# CY8C5888LTI_LP097 register map
File version: 0.1
CY8C58LP
Registers are 8-bit, read-write, no defined reset value unless marked. A register's access mark holds for its fields unless they carry their own. Offsets are from the block's base; lines under a group give offsets from that group; [hi:lo] are bit positions; {n}, {i} and the like mark numbered series; 'fields as' and 'values as' point back to an identical list; <NAME> marks a mode.

## Memory map
0x00000000 checkWatchDogTimer
0x00000000 SleepTimer
0x00000000 UART
0x00000000 PWM_Recon
0x00000000 Out_Comp
0x00000000 Bit_Timer

## checkWatchDogTimer
Base 0x00000000
0x40006504 checkWatchDogTimer_COUNTER 32-bit — UDB.A0 - Current Down Counter Value
0x40006524 checkWatchDogTimer_PERIOD 32-bit — UDB.D0 - Assigned Period
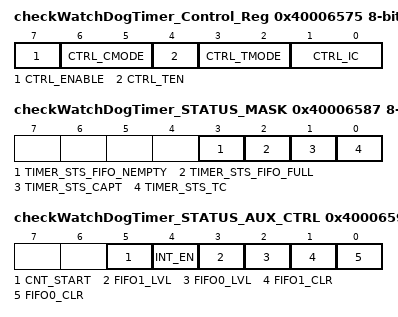
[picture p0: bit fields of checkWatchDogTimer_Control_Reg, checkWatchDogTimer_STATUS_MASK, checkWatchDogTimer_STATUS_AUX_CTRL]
0x40006575 checkWatchDogTimer_Control_Reg — UDB Control Register - Assigned Control Register Value
  [7] CTRL_ENABLE — Enable the Timer
  [6:5] CTRL_CMODE — Capture Mode
  [4] CTRL_TEN — Trigger Enable Bit
  [3:2] CTRL_TMODE — Trigger Mode
  [1:0] CTRL_IC — Interrupt Count
0x40006587 checkWatchDogTimer_STATUS_MASK — UDB Status bits Interrupt Mask Enable Register
  [3] TIMER_STS_FIFO_NEMPTY ro — FIFO Empty status
  [2] TIMER_STS_FIFO_FULL ro — FIFO Full Status
  [1] TIMER_STS_CAPT ro — Enables the Interrupt on Capture
  [0] TIMER_STS_TC ro — Enables the Interrupt on TC
0x40006597 checkWatchDogTimer_STATUS_AUX_CTRL — UDB Auxilliary Control Register
  [5] CNT_START — FIFO0 clear
    0=E_CNT_START0 (Disable counter); 1=E_CNT_START1 (Enable counter)
  [4] INT_EN
    0=E_INT_EN0 (Interrupt disabled); 1=E_INT_EN1 (Interrupt enabled)
  [3] FIFO1_LVL — FIFO level
    0=E_FIFO_LVL_0 (FIFO LVL: input mode: FIFO not full; output mode: FIFO not empty); 1=E_FIFO_LVL_1 (FIFO LVL: input mode: FIFO at least 1/2 empty; output mode: FIFO at least 1/2 full)
  [2] FIFO0_LVL — FIFO level
    values as FIFO1_LVL
  [1] FIFO1_CLR — FIFO1 clear
    0=E_FIFO_CLR_0 (Normal FIFO operation); 1=E_FIFO_CLR_1 (Clear FIFO state)
  [0] FIFO0_CLR — FIFO0 clear
    values as FIFO1_CLR

## SleepTimer
Base 0x00000000
0x40004381 SleepTimer_CTW_INTERVAL_REG — Timewheel Configuration Register 1
  [3:0] ctw_interval — Sets the central timewheel interval.
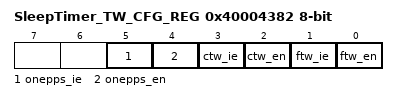
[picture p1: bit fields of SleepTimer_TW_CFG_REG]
0x40004382 SleepTimer_TW_CFG_REG — Timewheel Configuration Register 2
  [5] onepps_ie — When set and one pulse-per-second is enabled, an interrupt is issued when the pulse occurs.
    1=Enabled (One PPS interrupt is enabled); 0=Disabled (One PPS interrupt is disabled)
  [4] onepps_en — When set, the system returns to the active global power mode once every second.
    1=Enabled (One PPS is enabled); 0=Disabled (One PPS is disabled)
  [3] ctw_ie — When set and the central timewheel is enabled, an interrupt is issued when the central timewheel reaches the selected interval.
    1=Enabled (CTW interrupt is enabled); 0=Disabled (CTW interrupt is disabled)
  [2] ctw_en — When set, the system returns to the active global power mode when the central timewheel reaches the selected interval.
    1=Enabled (CTW is enabled); 0=Disabled (CTW is disabled)
  [1] ftw_ie — When set and the fast timewheel is enabled, an interrupt is issued when it reaches the terminal count.
    1=Enabled (FTW interrupt is enabled); 0=Disabled (FTW interrupt is disabled)
  [0] ftw_en — When set, the system returns to the active global power mode when the fast timewheel reaches the selected interval.
    1=Enabled (FTW is enabled); 0=Disabled (FTW is disabled)

## UART
Base 0x00000000
0x4000652A RX_UART_RX_ADDRESS1 — RX Address1 Register
0x4000653A RX_UART_RX_ADDRESS2 — RX Address2 Register
0x4000654A RX_UART_RX_DATA — RX Data Register
0x4000654B TX_UART_TX_DATA — TX Data Register
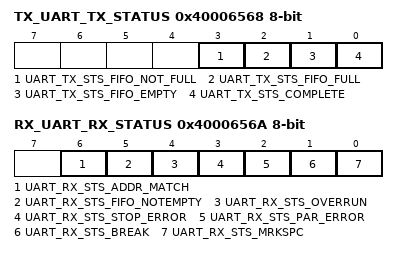
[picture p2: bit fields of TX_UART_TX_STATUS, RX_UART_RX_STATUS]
0x40006568 TX_UART_TX_STATUS — TX status register
  [3] UART_TX_STS_FIFO_NOT_FULL ro, [2] UART_TX_STS_FIFO_FULL ro, [1] UART_TX_STS_FIFO_EMPTY ro, [0] UART_TX_STS_COMPLETE ro
0x4000656A RX_UART_RX_STATUS — RX status register
  [6] UART_RX_STS_ADDR_MATCH ro, [5] UART_RX_STS_FIFO_NOTEMPTY ro, [4] UART_RX_STS_OVERRUN ro, [3] UART_RX_STS_STOP_ERROR ro, [2] UART_RX_STS_PAR_ERROR ro, [1] UART_RX_STS_BREAK ro, [0] UART_RX_STS_MRKSPC ro
